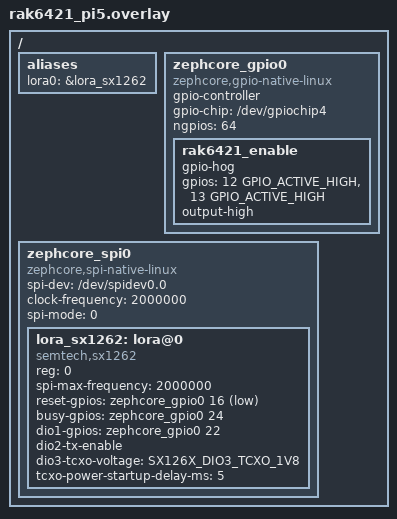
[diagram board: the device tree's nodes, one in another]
/*
 * SPDX-License-Identifier: Apache-2.0
 *
 * RAK6421 WisBlock Pi HAT + RAK13300/RAK13302 (SX1262), IO Slot 1, on Pi 5.
 * Auto-paired with rak6421_pi5.conf. Identical to rak6421.overlay except the
 * Pi 5 moved the 40-pin header GPIOs to /dev/gpiochip4.
 *
 * Pins + clock per the RAK6421 IO Slot 1 reference wiring, BCM numbering:
 *   CS = GPIO 8 (spidev0.0 CE0), DIO1 = GPIO 22, RESET = GPIO 16, BUSY = GPIO 24,
 *   DIO2 = RF switch, DIO3 = 1.8V TCXO, Enable_Pins 12+13 held high (GPIO hogs;
 *   needs CONFIG_GPIO_HOGS=y in rak6421_pi5.conf). Same wiring as rak6421.overlay,
 *   which is hardware-verified on a Pi Zero 2 W (2026-06-03); the Pi 5 gpiochip4
 *   variant is build-verified but not separately hardware-tested.
 */

#include <zephyr/dt-bindings/gpio/gpio.h>
#include <zephyr/dt-bindings/lora/sx126x.h>

/ {
	aliases {
		lora0 = &lora_sx1262;
	};

	zephcore_gpio0: zephcore_gpio0 {
		status = "okay";
		compatible = "zephcore,gpio-native-linux";
		gpio-controller;
		gpio-chip = "/dev/gpiochip4";
		ngpios = <64>;
		#gpio-cells = <2>;

		/* RAK6421 Enable_Pins: held high at boot to enable the RF front-end. */
		rak6421_enable {
			gpio-hog;
			gpios = <12 GPIO_ACTIVE_HIGH>, <13 GPIO_ACTIVE_HIGH>;
			output-high;
		};
	};

	zephcore_spi0: zephcore_spi0 {
		status = "okay";
		compatible = "zephcore,spi-native-linux";
		spi-dev = "/dev/spidev0.0";
		clock-frequency = <2000000>;
		spi-mode = <0>;
		#address-cells = <1>;
		#size-cells = <0>;
		/* CS is spidev0.0's HARDWARE CE0 (BCM GPIO 8). With dtparam=spi=on
		 * the kernel SPI controller owns that pin (ALT0), so it canNOT be
		 * grabbed as a GPIO — spidev asserts CE0 on every transfer instead.
		 * Do NOT declare cs-gpios here (that's the Femtofox path, where CS is
		 * a free GPIO). */

		lora_sx1262: lora@0 {
			compatible = "semtech,sx1262";
			reg = <0>;
			spi-max-frequency = <2000000>;
			reset-gpios = <&zephcore_gpio0 16 GPIO_ACTIVE_LOW>;
			busy-gpios  = <&zephcore_gpio0 24 GPIO_ACTIVE_HIGH>;
			dio1-gpios  = <&zephcore_gpio0 22 GPIO_ACTIVE_HIGH>;
			dio2-tx-enable;
			dio3-tcxo-voltage = <SX126X_DIO3_TCXO_1V8>;
			tcxo-power-startup-delay-ms = <5>;
		};
	};
};
